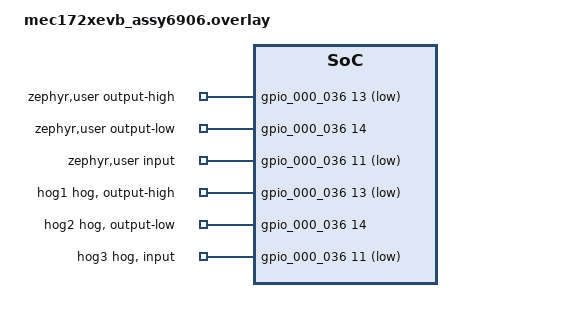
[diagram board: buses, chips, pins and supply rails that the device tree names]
/*
 * Copyright (c) 2023 Microchip Technology Inc.
 *
 * SPDX-License-Identifier: Apache-2.0
 */

#include <zephyr/dt-bindings/gpio/gpio.h>

/ {
	zephyr,user {
		output-high-gpios = <&gpio_000_036 13 GPIO_ACTIVE_LOW>;
		output-low-gpios = <&gpio_000_036 14 GPIO_ACTIVE_HIGH>;
		input-gpios = <&gpio_000_036 11 GPIO_ACTIVE_LOW>;
	};
};

&gpio_000_036 {
	hog1 {
		gpio-hog;
		gpios = <13 GPIO_ACTIVE_LOW>;
		output-high;
	};

	hog2 {
		gpio-hog;
		gpios = <14 GPIO_ACTIVE_HIGH>;
		output-low;
	};

	hog3 {
		gpio-hog;
		gpios = <11 GPIO_ACTIVE_LOW>;
		input;
	};
};
